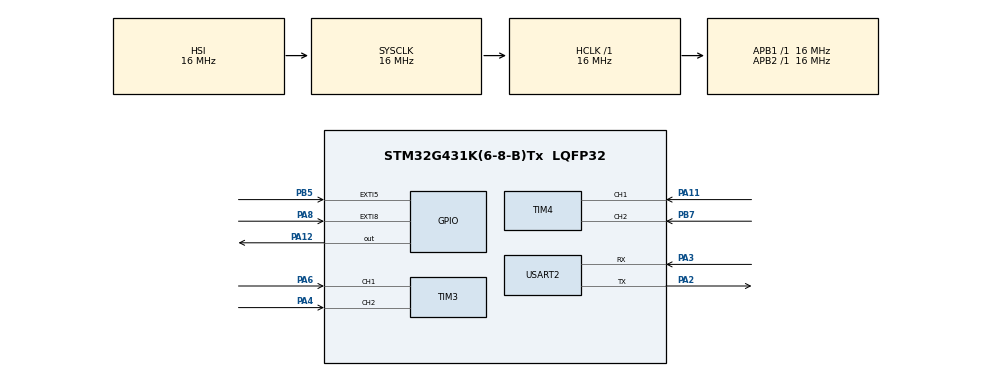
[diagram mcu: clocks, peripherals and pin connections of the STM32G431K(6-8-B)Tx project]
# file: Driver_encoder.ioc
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Mcu.Family=STM32G4
Mcu.Name=STM32G431K(6-8-B)Tx
Mcu.Package=LQFP32
NVIC.EXTI9_5_IRQn=true\:0\:0\:false\:false\:true\:true\:true\:true
NVIC.PriorityGroup=NVIC_PRIORITYGROUP_4
PA11.Signal=S_TIM4_CH1
PA12.Signal=GPIO_Output
PA2.Mode=Asynchronous
PA2.Signal=USART2_TX
PA3.Mode=Asynchronous
PA3.Signal=USART2_RX
PA4.Signal=S_TIM3_CH2
PA6.Signal=S_TIM3_CH1
PA8.Signal=GPXTI8
PB5.Signal=GPXTI5
PB7.Signal=S_TIM4_CH2
ProjectManager.HeapSize=0x200
ProjectManager.StackSize=0x400
ProjectManager.TargetToolchain=STM32CubeIDE
RCC.AHBFreq_Value=16000000
RCC.APB1Freq_Value=16000000
RCC.APB1TimFreq_Value=16000000
RCC.APB2Freq_Value=16000000
RCC.APB2TimFreq_Value=16000000
RCC.CortexFreq_Value=16000000
RCC.EXTERNAL_CLOCK_VALUE=12288000
RCC.HCLKFreq_Value=16000000
RCC.HSE_VALUE=8000000
RCC.HSI48_VALUE=48000000
RCC.HSI_VALUE=16000000
RCC.LSE_VALUE=32768
RCC.SYSCLKFreq_VALUE=16000000
RCC.USBFreq_Value=64000000
RCC.VCOOutputFreq_Value=128000000
SH.S_TIM3_CH1.0=TIM3_CH1,Encoder_Interface
SH.S_TIM3_CH2.0=TIM3_CH2,Encoder_Interface
SH.S_TIM4_CH1.0=TIM4_CH1,Encoder_Interface
SH.S_TIM4_CH2.0=TIM4_CH2,Encoder_Interface
USART2.VirtualMode-Asynchronous=VM_ASYNC
board=custom

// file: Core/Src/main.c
/* USER CODE BEGIN Header */
/**
  ******************************************************************************
  * @file           : main.c
  * @brief          : Main program body
  ******************************************************************************
  * @attention
  *
  * Copyright (c) 2023 STMicroelectronics.
  * All rights reserved.
  *
  * This software is licensed under terms that can be found in the LICENSE file
  * in the root directory of this software component.
  * If no LICENSE file comes with this software, it is provided AS-IS.
  *
  ******************************************************************************
  */
/* USER CODE END Header */
#include "main.h"

/* USER CODE BEGIN Includes */
#include <stdio.h>
#include "Encoder.h"
/* USER CODE END Includes */

/* USER CODE BEGIN PD */
    uint32_t counter = 0;
    int turned_round =0;
    float distance_current =0.0;

/* USER CODE END PD */

TIM_HandleTypeDef htim3;
TIM_HandleTypeDef htim4;

UART_HandleTypeDef huart2;

void SystemClock_Config(void);
static void MX_GPIO_Init(void);
static void MX_TIM3_Init(void);
static void MX_USART2_UART_Init(void);
static void MX_TIM4_Init(void);
/* USER CODE BEGIN PFP */
void User_TIMIndexEncoderCallback(TIM_HandleTypeDef *htim);

/* USER CODE END PFP */

int main(void)
{

  /* MCU Configuration--------------------------------------------------------*/

  /* Reset of all peripherals, Initializes the Flash interface and the Systick. */
  HAL_Init();

  /* Configure the system clock */
  SystemClock_Config();

  /* Initialize all configured peripherals */
  MX_GPIO_Init();
  MX_TIM3_Init();
  MX_USART2_UART_Init();
  MX_TIM4_Init();
  /* USER CODE BEGIN 2 */

  Encoder_Init(&htim3, &htim4);
  Encoder_Start_Record();
  HAL_Delay(5000);

  //sprintf(MSG, "%d", (int)Encoder_Right_Get_Distance());
  //HAL_UART_Transmit(&huart2, MSG, sizeof(MSG), 100);
  Encoder_Start_Record();
  /* USER CODE END 2 */

  /* Infinite loop */
  /* USER CODE BEGIN WHILE */
  while (1)
  {

	  counter = __HAL_TIM_GET_COUNTER(&htim3);
	  turned_round = Encoder_Get_Number_Turned_Round();
	  distance_current = Encoder_Left_Get_Distance();

  }
    /* USER CODE END WHILE */

}

void SystemClock_Config(void)
{
  RCC_OscInitTypeDef RCC_OscInitStruct = {0};
  RCC_ClkInitTypeDef RCC_ClkInitStruct = {0};

  /** Configure the main internal regulator output voltage
  */
  HAL_PWREx_ControlVoltageScaling(PWR_REGULATOR_VOLTAGE_SCALE1);

  /** Initializes the RCC Oscillators according to the specified parameters
  * in the RCC_OscInitTypeDef structure.
  */
  RCC_OscInitStruct.OscillatorType = RCC_OSCILLATORTYPE_HSI;
  RCC_OscInitStruct.HSIState = RCC_HSI_ON;
  RCC_OscInitStruct.HSICalibrationValue = RCC_HSICALIBRATION_DEFAULT;
  RCC_OscInitStruct.PLL.PLLState = RCC_PLL_NONE;
  if (HAL_RCC_OscConfig(&RCC_OscInitStruct) != HAL_OK)
  {
    Error_Handler();
  }

  /** Initializes the CPU, AHB and APB buses clocks
  */
  RCC_ClkInitStruct.ClockType = RCC_CLOCKTYPE_HCLK|RCC_CLOCKTYPE_SYSCLK
                              |RCC_CLOCKTYPE_PCLK1|RCC_CLOCKTYPE_PCLK2;
  RCC_ClkInitStruct.SYSCLKSource = RCC_SYSCLKSOURCE_HSI;
  RCC_ClkInitStruct.AHBCLKDivider = RCC_SYSCLK_DIV1;
  RCC_ClkInitStruct.APB1CLKDivider = RCC_HCLK_DIV1;
  RCC_ClkInitStruct.APB2CLKDivider = RCC_HCLK_DIV1;

  if (HAL_RCC_ClockConfig(&RCC_ClkInitStruct, FLASH_LATENCY_0) != HAL_OK)
  {
    Error_Handler();
  }
}

static void MX_TIM3_Init(void)
{

  TIM_Encoder_InitTypeDef sConfig = {0};
  TIM_MasterConfigTypeDef sMasterConfig = {0};

  htim3.Instance = TIM3;
  htim3.Init.Prescaler = 0;
  htim3.Init.CounterMode = TIM_COUNTERMODE_UP;
  htim3.Init.Period = 65535;
  htim3.Init.ClockDivision = TIM_CLOCKDIVISION_DIV1;
  htim3.Init.AutoReloadPreload = TIM_AUTORELOAD_PRELOAD_DISABLE;
  sConfig.EncoderMode = TIM_ENCODERMODE_TI1;
  sConfig.IC1Polarity = TIM_ICPOLARITY_RISING;
  sConfig.IC1Selection = TIM_ICSELECTION_DIRECTTI;
  sConfig.IC1Prescaler = TIM_ICPSC_DIV1;
  sConfig.IC1Filter = 0;
  sConfig.IC2Polarity = TIM_ICPOLARITY_RISING;
  sConfig.IC2Selection = TIM_ICSELECTION_DIRECTTI;
  sConfig.IC2Prescaler = TIM_ICPSC_DIV1;
  sConfig.IC2Filter = 0;
  if (HAL_TIM_Encoder_Init(&htim3, &sConfig) != HAL_OK)
  {
    Error_Handler();
  }
  sMasterConfig.MasterOutputTrigger = TIM_TRGO_RESET;
  sMasterConfig.MasterSlaveMode = TIM_MASTERSLAVEMODE_DISABLE;
  if (HAL_TIMEx_MasterConfigSynchronization(&htim3, &sMasterConfig) != HAL_OK)
  {
    Error_Handler();
  }

}

static void MX_TIM4_Init(void)
{

  TIM_Encoder_InitTypeDef sConfig = {0};
  TIM_MasterConfigTypeDef sMasterConfig = {0};

  htim4.Instance = TIM4;
  htim4.Init.Prescaler = 0;
  htim4.Init.CounterMode = TIM_COUNTERMODE_UP;
  htim4.Init.Period = 65535;
  htim4.Init.ClockDivision = TIM_CLOCKDIVISION_DIV1;
  htim4.Init.AutoReloadPreload = TIM_AUTORELOAD_PRELOAD_DISABLE;
  sConfig.EncoderMode = TIM_ENCODERMODE_TI1;
  sConfig.IC1Polarity = TIM_ICPOLARITY_RISING;
  sConfig.IC1Selection = TIM_ICSELECTION_DIRECTTI;
  sConfig.IC1Prescaler = TIM_ICPSC_DIV1;
  sConfig.IC1Filter = 0;
  sConfig.IC2Polarity = TIM_ICPOLARITY_RISING;
  sConfig.IC2Selection = TIM_ICSELECTION_DIRECTTI;
  sConfig.IC2Prescaler = TIM_ICPSC_DIV1;
  sConfig.IC2Filter = 0;
  if (HAL_TIM_Encoder_Init(&htim4, &sConfig) != HAL_OK)
  {
    Error_Handler();
  }
  sMasterConfig.MasterOutputTrigger = TIM_TRGO_RESET;
  sMasterConfig.MasterSlaveMode = TIM_MASTERSLAVEMODE_DISABLE;
  if (HAL_TIMEx_MasterConfigSynchronization(&htim4, &sMasterConfig) != HAL_OK)
  {
    Error_Handler();
  }

}

static void MX_USART2_UART_Init(void)
{

  huart2.Instance = USART2;
  huart2.Init.BaudRate = 115200;
  huart2.Init.WordLength = UART_WORDLENGTH_8B;
  huart2.Init.StopBits = UART_STOPBITS_1;
  huart2.Init.Parity = UART_PARITY_NONE;
  huart2.Init.Mode = UART_MODE_TX_RX;
  huart2.Init.HwFlowCtl = UART_HWCONTROL_NONE;
  huart2.Init.OverSampling = UART_OVERSAMPLING_16;
  huart2.Init.OneBitSampling = UART_ONE_BIT_SAMPLE_DISABLE;
  huart2.Init.ClockPrescaler = UART_PRESCALER_DIV1;
  huart2.AdvancedInit.AdvFeatureInit = UART_ADVFEATURE_NO_INIT;
  if (HAL_UART_Init(&huart2) != HAL_OK)
  {
    Error_Handler();
  }
  if (HAL_UARTEx_SetTxFifoThreshold(&huart2, UART_TXFIFO_THRESHOLD_1_8) != HAL_OK)
  {
    Error_Handler();
  }
  if (HAL_UARTEx_SetRxFifoThreshold(&huart2, UART_RXFIFO_THRESHOLD_1_8) != HAL_OK)
  {
    Error_Handler();
  }
  if (HAL_UARTEx_DisableFifoMode(&huart2) != HAL_OK)
  {
    Error_Handler();
  }

}

static void MX_GPIO_Init(void)
{
  GPIO_InitTypeDef GPIO_InitStruct = {0};

  /* GPIO Ports Clock Enable */
  __HAL_RCC_GPIOA_CLK_ENABLE();
  __HAL_RCC_GPIOB_CLK_ENABLE();

  /*Configure GPIO pin Output Level */
  HAL_GPIO_WritePin(GPIOA, GPIO_PIN_12, GPIO_PIN_RESET);

  /*Configure GPIO pin : PA8 */
  GPIO_InitStruct.Pin = GPIO_PIN_8;
  GPIO_InitStruct.Mode = GPIO_MODE_IT_RISING;
  GPIO_InitStruct.Pull = GPIO_NOPULL;
  HAL_GPIO_Init(GPIOA, &GPIO_InitStruct);

  /*Configure GPIO pin : PA12 */
  GPIO_InitStruct.Pin = GPIO_PIN_12;
  GPIO_InitStruct.Mode = GPIO_MODE_OUTPUT_PP;
  GPIO_InitStruct.Pull = GPIO_NOPULL;
  GPIO_InitStruct.Speed = GPIO_SPEED_FREQ_LOW;
  HAL_GPIO_Init(GPIOA, &GPIO_InitStruct);

  /*Configure GPIO pin : PB5 */
  GPIO_InitStruct.Pin = GPIO_PIN_5;
  GPIO_InitStruct.Mode = GPIO_MODE_IT_RISING;
  GPIO_InitStruct.Pull = GPIO_NOPULL;
  HAL_GPIO_Init(GPIOB, &GPIO_InitStruct);

  /* EXTI interrupt init*/
  HAL_NVIC_SetPriority(EXTI9_5_IRQn, 0, 0);
  HAL_NVIC_EnableIRQ(EXTI9_5_IRQn);

}

void Error_Handler(void)
{
  __disable_irq();
  while (1)
  {
  }
}
